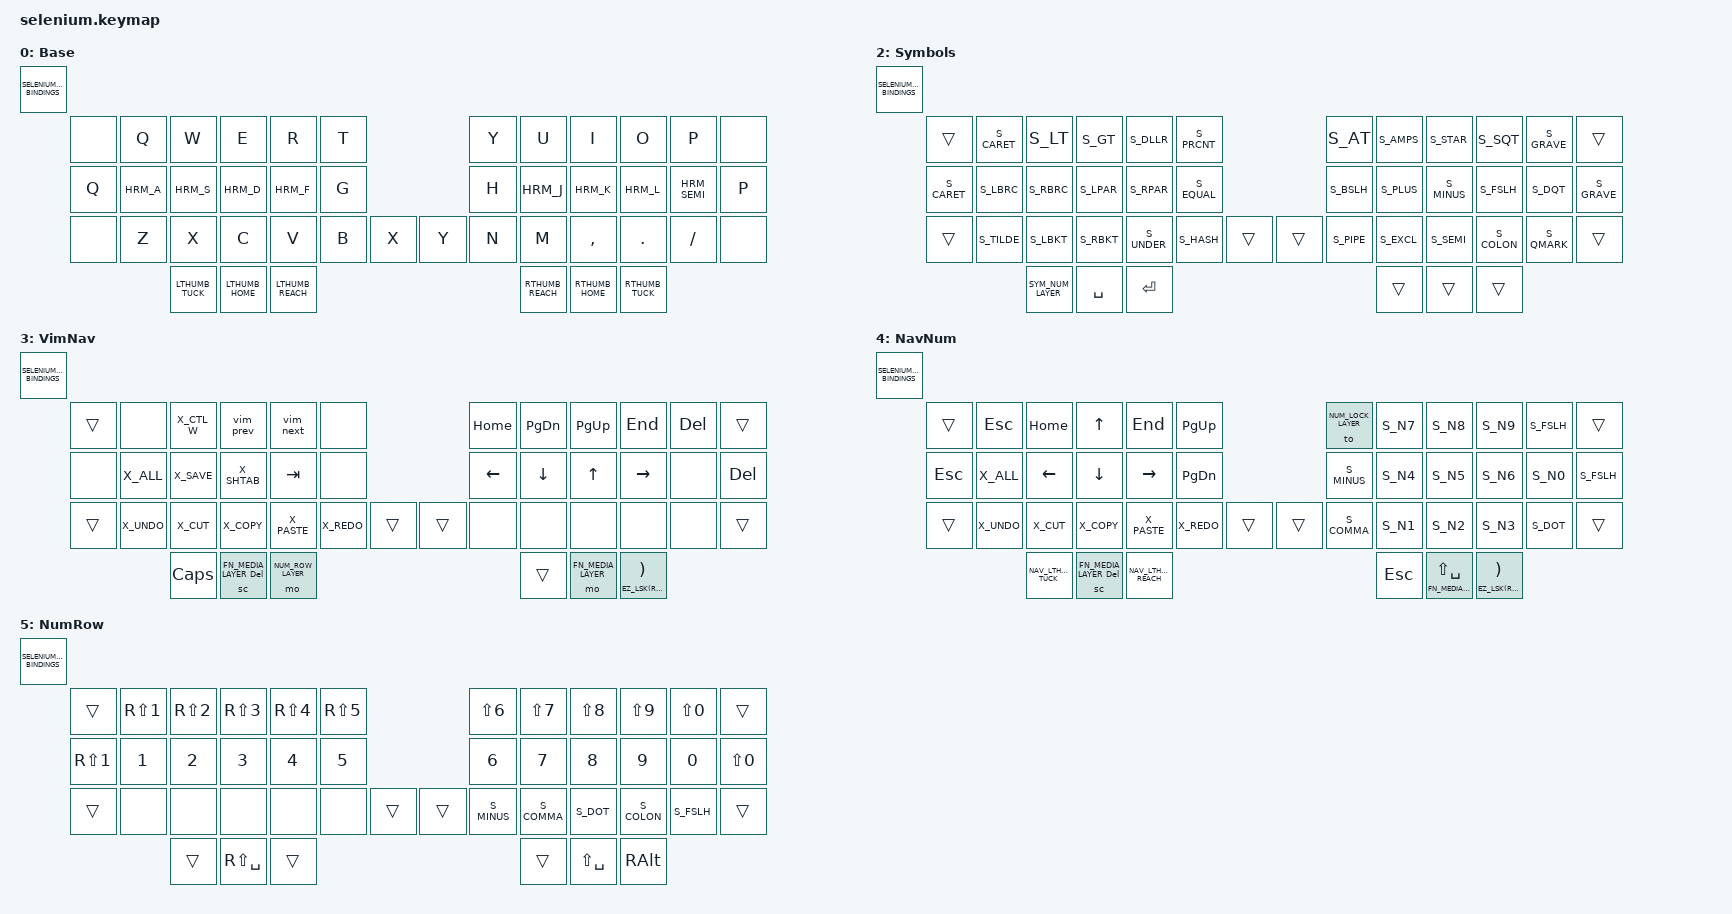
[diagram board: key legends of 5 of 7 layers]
// Selenium keymap:
// https://github.com/OneDeadKey/selenium

#include <dt-bindings/zmk/bt.h> // bluetooth behaviors (see fn/media layer)

#ifndef CI_IGNORE_USER_SETTINGS
  #include "settings.h"   // user settings
#endif

#include "defaults.h"     // default options and safeguards
#include "aliases.h"      // defines symbols and actions
#include "bindings.h"     // default SELENIUM_KEYMAP_BINDINGS macro
#include "mappings.dtsi"  // key mapping helpers and macros
#include "hold_taps.dtsi" // defines thumb keys and homerow mods

/**
 * All keyboard layers are defined by blocks on a 42-key basis, as follows:
 *
 *   <SELENIUM_KEYMAP_BINDINGS(
 *     Tab   , QWERT , YUIOP , BkSpc ,
 *     Esc   , ASDFG , HJKL: , Enter ,
 *     Shift , ZXCVB , NM<>? , Shift ,
 *      LT1, LT2, LT3, RT3, RT2, RT1
 *   )>
 *
 * Where LTx/RTx are the left/right thumb keys.
 * Beware: missing or misplacing a comma in the definitions below would break the keymap.
 */

/ {
  keymap {
    compatible = "zmk,keymap";

    // 0. Base layer -- keep the QWERTY key codes to use your OS keyboard layout
    //               -- the Space Cadet layer-tap on the right can be replaced by an AltGr/Enter mod-tap
    //               -- adjust the homerow mods with the #define statements above
    base_layer: base_layer {
      display-name = "Base";
      bindings = <SELENIUM_KEYMAP_BINDINGS(
        &none ,  &kp Q  &kp W  &kp E  &kp R  &kp T        ,         &kp Y  &kp U  &kp I     &kp O   &kp P     ,  &none ,
        &kp Q ,  HRM_A  HRM_S  HRM_D  HRM_F  &kp G        ,         &kp H  HRM_J  HRM_K     HRM_L   HRM_SEMI  ,  &kp P ,
        &none ,  &kp Z  &kp X  &kp C  &kp V  &kp B, &kp X , &kp Y , &kp N  &kp M  &kp COMMA &kp DOT &kp FSLH  ,  &none ,
                      LTHUMB_TUCK , LTHUMB_HOME , LTHUMB_REACH , RTHUMB_REACH , RTHUMB_HOME , RTHUMB_TUCK
      )>;
      sensor-bindings = <&inc_dec_kp C_VOL_UP C_VOL_DN &scroll_encoder SCRL_UP SCRL_DOWN>;
    };

    // 1. NumLock layer -- a NavNum layer that stays on until deactivated without holding any key
    num_lock_layer: num_lock_layer {
      display-name = "NumLock";
      bindings = <SELENIUM_KEYMAP_BINDINGS(
        &trans  ,  &kp ESC  &kp HOME &kp UP   &kp END   &kp PG_UP          ,          &to BASE_LAYER S_N7  S_N8  S_N9  S_FSLH  ,  &trans ,
        &kp ESC  ,  S_EQUAL  &kp LEFT &kp DOWN &kp RIGHT &kp PG_DN          ,          S_MINUS        S_N4  S_N5  S_N6  S_N0    ,  S_FSLH ,
        &trans  ,  S_MONEY  S_COLON  S_STAR   S_PLUS    S_PRCNT   , &trans , &trans , S_COMMA        S_N1  S_N2  S_N3  S_DOT   ,  &trans ,
                          &trans , &sc NAV_NUM_LAYER BACKSPACE , &kp (TAB) , &trans , &lt NAV_NUM_LAYER LS(SPACE) , &EZ_SL(SYMBOLS_LAYER)
      )>;
    };

    // 2. Symbols layer -- with Ergol, basically just an AltGr layer with custom thumb keys
    //                  -- can be redefined for non-AltGr layouts such as QWERTY-ANSI
    symbols_layer: symbols_layer {
      display-name = "Symbols";
      bindings = <SELENIUM_KEYMAP_BINDINGS(
        &trans  ,  S_CARET S_LT    S_GT    S_DLLR  S_PRCNT          ,          S_AT    S_AMPS  S_STAR  S_SQT   S_GRAVE  ,  &trans ,
        S_CARET  ,  S_LBRC  S_RBRC  S_LPAR  S_RPAR  S_EQUAL          ,          S_BSLH  S_PLUS  S_MINUS S_FSLH  S_DQT    ,  S_GRAVE ,
        &trans  ,  S_TILDE S_LBKT  S_RBKT  S_UNDER S_HASH  , &trans , &trans , S_PIPE  S_EXCL  S_SEMI  S_COLON S_QMARK  ,  &trans ,
                              SYM_NUM_LAYER , &kp SPACE , &kp ENTER , &trans , &trans ,  &trans
      )>;
    };

    // 3. VimNav layer -- HJKL arrow cluster on the right hand
    //                 -- best used along with the NumRow layer
    //                 -- keyboard shortcuts on the left hand are adjusted to the OS layout (Ergol here)
    vim_nav_layer: vim_nav_layer {
      display-name = "VimNav";
      bindings = <SELENIUM_KEYMAP_BINDINGS(
        &trans  ,  &none    X_CTL_W  &vim_prev &vim_next &none           ,          &kp HOME &kp PG_DN &kp PG_UP &kp END   &kp DEL ,  &trans ,
        &none  ,  X_ALL    X_SAVE   X_SHTAB   &kp TAB   &none           ,          &kp LEFT &kp DOWN  &kp UP    &kp RIGHT &none   ,  &kp DEL ,
        &trans  ,  X_UNDO   X_CUT    X_COPY    X_PASTE   X_REDO , &trans , &trans , &none    &none     &none     &none     &none   ,  &trans ,
                   &kp CAPS , &sc FN_MEDIA_LAYER DEL , &mo NUM_ROW_LAYER , &trans , &mo FN_MEDIA_LAYER , &EZ_LSK(RALT)
      )>;
    };

    // 4. NavNum layer -- inverted T arrow cluster on the left hand, numpad on the right hand
    //                 -- can be the only extra layer you need if you're not too picky with number+symbols n-grams
    //                 -- keyboard shortcuts on the left hand are adjusted to the OS layout (Ergol here)
    nav_num_layer: nav_num_layer {
      display-name = "NavNum";
      bindings = <SELENIUM_KEYMAP_BINDINGS(
        &trans  ,  &kp ESC  &kp HOME &kp UP   &kp END   &kp PG_UP          ,           &to NUM_LOCK_LAYER S_N7  S_N8  S_N9  S_FSLH  ,  &trans ,
        &kp ESC  ,  X_ALL    &kp LEFT &kp DOWN &kp RIGHT &kp PG_DN          ,           S_MINUS            S_N4  S_N5  S_N6  S_N0    ,  S_FSLH ,
        &trans  ,  X_UNDO   X_CUT    X_COPY   X_PASTE   X_REDO    , &trans , &trans  , S_COMMA            S_N1  S_N2  S_N3  S_DOT   ,  &trans ,
               NAV_LTHUMB_TUCK , &sc FN_MEDIA_LAYER DEL , NAV_LTHUMB_REACH , &kp ESCAPE , &lt FN_MEDIA_LAYER LS(SPACE) , &EZ_LSK(RALT)
      )>;
    };

    // 5. NumRow layer -- bring the numbers to the homerow, keep shift+numbers for shortcuts and symbols
    //                 -- space becomes shift+space, which is a no-break space with some OS layouts (e.g. Ergol)
    //                 -- best used along with the VimNav layer
    num_row_layer: num_row_layer {
      display-name = "NumRow";
      bindings = <SELENIUM_KEYMAP_BINDINGS(
        &trans  ,  &kp RS(N1) &kp RS(N2) &kp RS(N3) &kp RS(N4) &kp RS(N5)        ,          &kp LS(N6) &kp LS(N7) &kp LS(N8) &kp LS(N9) &kp LS(N0)  ,  &trans ,
        &kp RS(N1)  ,  &kp N1     &kp N2     &kp N3     &kp N4     &kp N5            ,          &kp N6     &kp N7     &kp N8     &kp N9     &kp N0      ,  &kp LS(N0) ,
        &trans  ,  &none      &none      &none      &none      &none    , &trans , &trans , S_MINUS    S_COMMA    S_DOT      S_COLON    S_FSLH      ,  &trans ,
                                                 &trans , &kp RS(SPACE) , &trans , &trans , &kp LS(SPACE) , &kp RALT
      )>;
    };

    // 6. FnMedia layer -- F1..12 pad on the left hand, HRM on the right hand
    //                  -- reset and bootloader reset on difficult thumb keys
    //                  -- could be completed with other rare keys
    fn_media_layer: fn_media_layer {
      display-name = "FnMedia";
      bindings = <SELENIUM_KEYMAP_BINDINGS(
        &trans  ,  &kp F1  &kp F2  &kp F3  &kp F4  &none          ,          &bt BT_SEL 2  &kp C_NEXT  &kp C_VOL_UP  &kp C_BRI_UP   &kp SLCK      ,  &trans   ,
        &kp F1  ,  &kp F5  &kp F6  &kp F7  &kp F8  &none          ,          &bt_sel1_clr  H_J C_PP    H_K C_MUTE    H_L C_AL_LOCK  H_SEMI PSCRN  ,  &kp SLCK ,
        &trans  ,  &kp F9  &kp F10 &kp F11 &kp F12 &none , &trans , &trans , &bt BT_SEL 0  &kp C_PREV  &kp C_VOL_DN  &kp C_BRI_DN   &kp INS       ,  &trans   ,
                                    &trans , &bootloader , &trans , &trans , &sys_reset , &studio_unlock
      )>;
    };

  };
};

// Emulated layouts (experimental!)
#ifdef KB_EMULATION_DVORAK
  #include "emulations/dvorak.dtsi"
#elif defined KB_EMULATION_ERGOL
  #include "emulations/ergol.dtsi"
#elif defined KB_EMULATION_QWERTY_LAFAYETTE
  #include "emulations/qwerty_lafayette.dtsi"

// Some layouts require extra layers to fit on the Quacken.
#elif defined KB_LAYOUT_AZERTY
  #include "extra_layers/azerty.dtsi"
#elif defined KB_LAYOUT_BEPO
  #include "extra_layers/bepo.dtsi"
#elif defined KB_LAYOUT_ERGOL && defined HUMMINGBIRD
  #include "extra_layers/ergol_hummingbird.dtsi"
#endif
